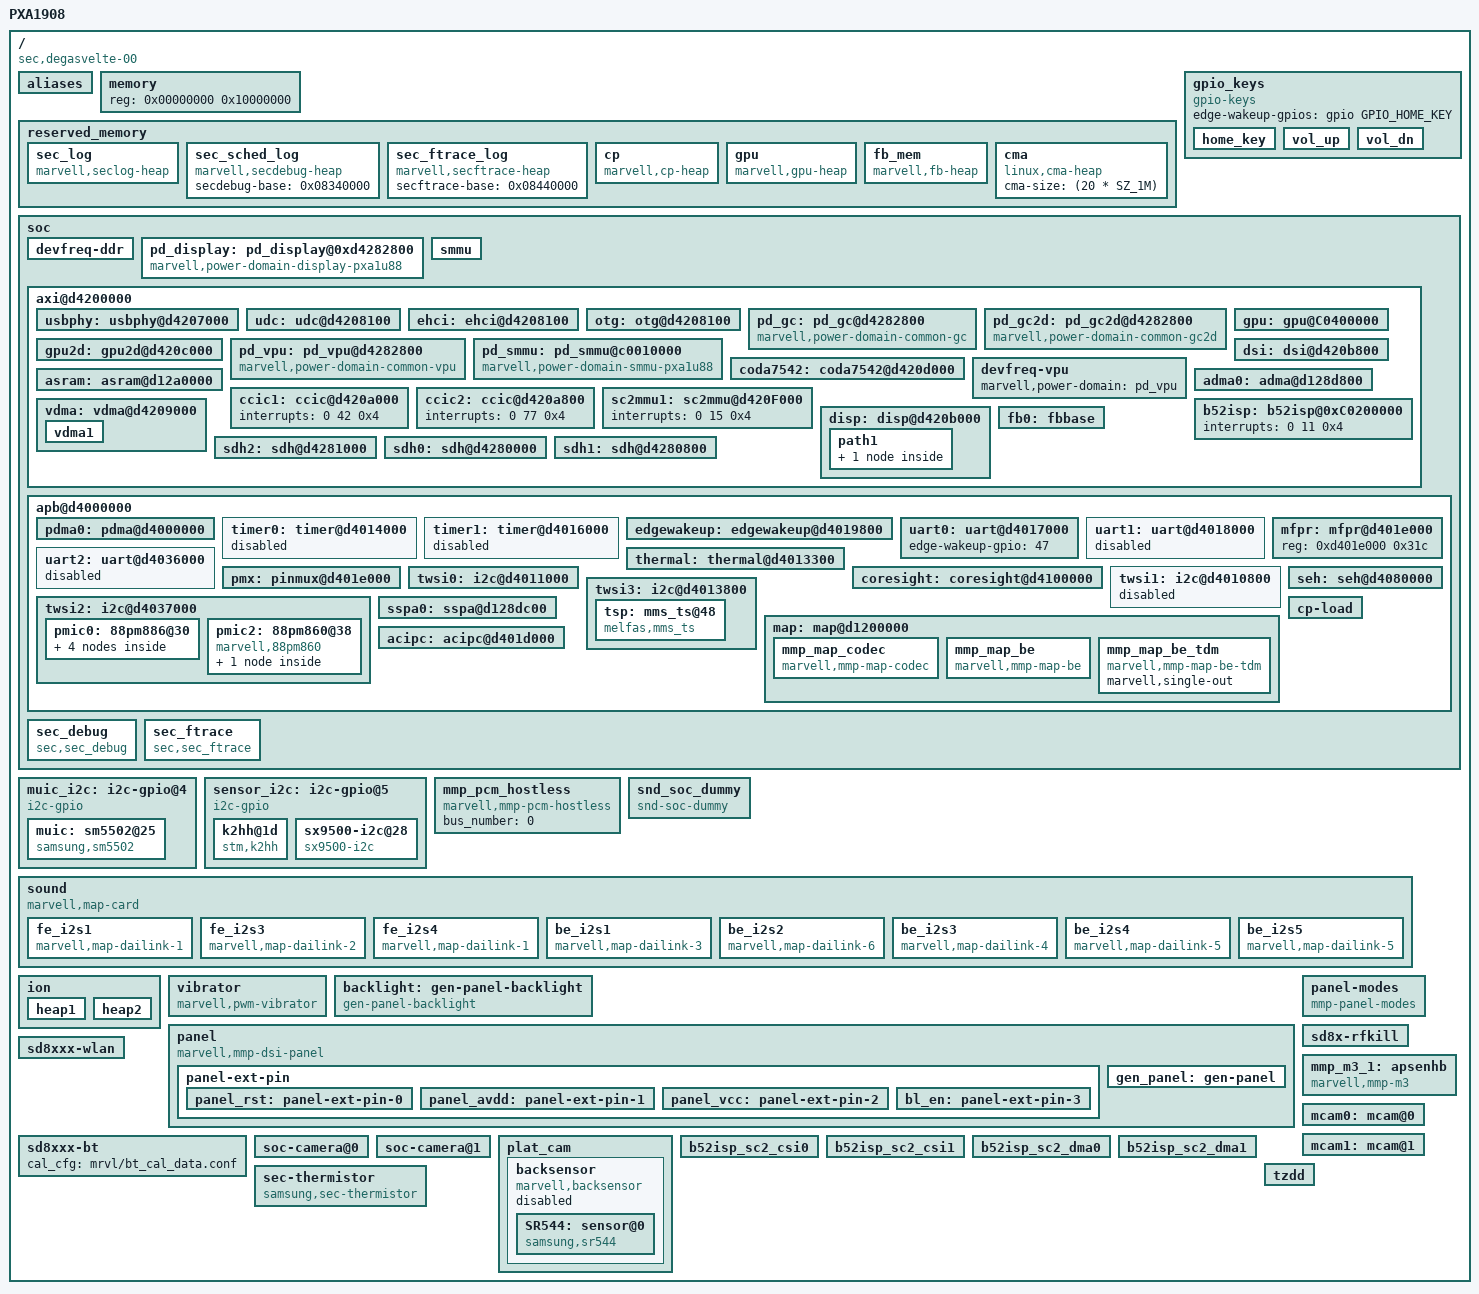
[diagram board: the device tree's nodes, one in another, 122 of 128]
/*
 *	Copyright (C) 2014 Marvell Technology Group Ltd.
 *	Copyright (C) 2014 Samsung Electronics Co, Ltd.
 *
 *	Most of configurations are taken from J1-LTE
 *
 *	This program is free software; you can redistribute it and/or modify
 *	it under the terms of the GNU General Public License version 2 as
 *	published by the Free Software Foundation.
 */

/dts-v1/;
/memreserve/ 0x0a000000 0x00080000;     /* CM3 shared buffer(512KB) */
#include "pxa1908.dtsi"
#include "pxa1908-pinfunc.h"
#include <dt-bindings/mmc/pxa_sdhci.h>
#include <dt-bindings/sizes.h>

#include "pxa1908-degasvelte-00-gpio.h"

#include "sec-machtypes.h"

#include <dt-bindings/input/input.h>
#include <dt-bindings/input/sec_input.h>

/ {
	model = "PXA1908";
	compatible = "sec,degasvelte-00", "marvell,pxa1908";
	pxa,rev-id = <MACH_TYPE_DEGASVELTE 0>;

	aliases {
		i2c4 = &muic_i2c;
		i2c5 = &sensor_i2c;
	};

	memory {
		reg = <0x00000000 0x10000000>;
	};

	reserved_memory {
		sec_log {
			compatible = "marvell,seclog-heap";
			seclog-base = <0x08140000>;
			seclog-size = <0x00100000>;
			seclastklog-base = <0x8240000>;
			seclastklog-size = <0x100000>;
			status = "okay";
		};

		sec_sched_log {
			compatible = "marvell,secdebug-heap";
			secdebug-base = <0x08340000>;
			status = "okay";
		};

		sec_ftrace_log {
			compatible = "marvell,secftrace-heap";
			secftrace-base = <0x08440000>;
			status = "okay";
		};

		cp {
			compatible = "marvell,cp-heap";
			cp-base = <0x05000000>;
			cp-size = <(48 * SZ_1M)>;
			status = "okay";
		};

		gpu {
			compatible = "marvell,gpu-heap";
			gpu-base = <0x09000000>;
			gpu-size = <(16 * SZ_1M)>;
			status = "okay";
		};

		fb_mem {
			compatible = "marvell,fb-heap";
			fb-mem = <0x17000000>;
			xres = <800>;
			yres = <1280>;
			bpp = <4>; /* bits per pixel = 32, so bytes per pixel = 32/8 = 4 */
			status = "okay";
		};

		cma {
			compatible = "linux,cma-heap";
			cma-size = <(20 * SZ_1M)>;
			status = "okay";
		};
	};

	gpio_keys: gpio_keys {	/* TODO: PINCTRL */
		compatible = "gpio-keys";
		edge-wakeup-gpios = <&gpio GPIO_HOME_KEY 0>;
		#address-cells = <1>;
		#size-cells = <0>;

		home_key {
			label = "HOME_KEY";
			linux,code = <KEY_HOMEPAGE>;
			gpios = <&gpio GPIO_HOME_KEY 1>;
		};

		vol_up {
			label = "VOL_UP";
			linux,code = <KEY_VOLUMEUP>;
			gpios = <&gpio GPIO_VOL_UP 1>;
		};

		vol_dn {
			label = "VOL_DN";
			linux,code = <KEY_VOLUMEDOWN>;
			gpios = <&gpio GPIO_VOL_DN 1>;
		};
	};

	soc {
		devfreq-ddr {
			status = "okay";
		};

		pd_display: pd_display@0xd4282800 {
			compatible = "marvell,power-domain-display-pxa1u88";
			reg = <0xd4282800 0x1000>;
			clocks = <&soc_clocks PXA1U88_CLK_DISP_HCLK>,
				<&soc_clocks PXA1U88_CLK_DSI_ESC>,
				<&soc_clocks PXA1U88_CLK_DISP1_EN>;
			clock-names = "LCDCIHCLK", "esc_clk", "disp1_clk_gate";
		};

		smmu {  /* iommu in vpu */
			clocks = <&soc_clocks PXA1U88_CLK_VPU>,
				<&soc_clocks PXA1U88_CLK_VPUBUS>;
			clock-names = "VPUCLK", "VPUACLK";
			marvell,power-domain = <&pd_vpu>;
			status = "okay";
		};

		axi@d4200000 {  /* AXI */
			usbphy: usbphy@d4207000 {
				status = "okay";
			};

			udc: udc@d4208100 {
				status = "okay";
			};

			ehci: ehci@d4208100 {
				status = "okay";
			};

			otg: otg@d4208100 {
				status = "okay";
			};

			pd_gc: pd_gc@d4282800 {
				compatible = "marvell,power-domain-common-gc";
				reg = <0xd4282800 0x1000>;
				clocks = <&soc_clocks PXA1U88_CLK_GC3D>;
				lpm-qos = <PM_QOS_CPUIDLE_BLOCK_DDR>;
			};

			pd_gc2d: pd_gc2d@d4282800 {
				compatible = "marvell,power-domain-common-gc2d";
				reg = <0xd4282800 0x1000>;
				clocks = <&soc_clocks PXA1U88_CLK_GC2D>;
				lpm-qos = <PM_QOS_CPUIDLE_BLOCK_DDR>;
			};

			gpu: gpu@C0400000 {
				marvell,power-domain = <&pd_gc>;
				marvell,gpu-mem-base = <0x09000000>;
				marvell,gpu-mem-size = <0x1000000>;
				clocks = <&soc_clocks PXA1U88_CLK_GC3D>,
					<&soc_clocks PXA1U88_CLK_GCSH>,
					<&soc_clocks PXA1U88_CLK_GCBUS>;
				clock-names = "GC3DFCLK", "GCSHCLK", "GC3DACLK";
				status = "okay";
			};

			gpu2d: gpu2d@d420c000 {
				marvell,power-domain = <&pd_gc2d>;
				clocks = <&soc_clocks PXA1U88_CLK_GC2D>,
					<&soc_clocks PXA1U88_CLK_GCBUS>;
				clock-names = "GC2DFCLK", "GC2DACLK";
				status = "okay";
			};

			pd_vpu: pd_vpu@d4282800 {
				compatible = "marvell,power-domain-common-vpu";
				reg = <0xd4282800 0x1000>;
				clocks = <&soc_clocks PXA1U88_CLK_VPU>;
				lpm-qos = <PM_QOS_CPUIDLE_BLOCK_DDR>;
			};

			pd_smmu: pd_smmu@c0010000 {
				compatible = "marvell,power-domain-smmu-pxa1u88";
				reg = <0xc0010000 0x10000>;
				marvell,power-domain-parent = <&pd_vpu>;
				clocks = <&soc_clocks PXA1U88_CLK_VPU>,
					<&soc_clocks PXA1U88_CLK_VPUBUS>;
				clock-names = "VPUCLK", "VPUACLK";
			};

			coda7542: coda7542@d420d000 {
				marvell,sram-internal = <0>;
				marvell,nv21_support = <1>;
				marvell,seconddaxi_none = <1>;
				marvell,power-domain = <&pd_smmu>;
				clocks = <&soc_clocks PXA1U88_CLK_VPU>,
					<&soc_clocks PXA1U88_CLK_VPUBUS>;
				clock-names = "VPUCLK", "VPUACLK";
				status = "okay";
			};

			devfreq-vpu {
				marvell,power-domain = <&pd_vpu>;
				status = "okay";
			};

			dsi: dsi@d420b800 {
				marvell,phy-name = "mmp_dsi1";
				marvell,plat-path-name = "mmp_pnpath";
				marvell,dsi-lanes = <4>;
				marvell,burst-mode = <2>;
				marvell,vsync-slave;
/*				marvell,hbp-en;*/
/*				marvell,hfp-en;*/
				status = "okay";
			};

			asram: asram@d12a0000 {
				status = "okay";
			};

			adma0: adma@d128d800 {
				status = "okay";
			};

			ccic1: ccic@d420a000 {	/* TODO: PINCTRL */
				interrupts = <0 42 0x4>;
				status = "okay";
			};

			ccic2: ccic@d420a800 {	/* TODO: PINCTRL */
				interrupts = <0 77 0x4>;
				status = "okay";
			};

			sc2mmu1: sc2mmu@d420F000 {
				interrupts = <0 15 0x4>;
				status = "okay";
			};

			b52isp: b52isp@0xC0200000 {
				interrupts = <0 11 0x4>;
				status = "okay";
			};

			vdma: vdma@d4209000 {
				marvell,vdma-num = <1>;
				marvell,vdma-axi = <1>;
				status = "okay";
				vdma1 {
					marvell,vdma-id = <0>;
					marvell,sram-size = <15360>;
					marvell,is_vid = <0>;
				};
			};

			disp: disp@d420b000 {
				pinctrl-names = "default";
				marvell,disp-name = "disp_name";
				marvell,path-num = <1>;
				marvell,power-domain = <&pd_display>;
				clocks = <&soc_clocks PXA1U88_CLK_DISP1>,
						<&soc_clocks PXA1U88_CLK_DISP4>;
				clock-names = "disp1_clk", "dsipll_clk";
				status = "okay";
				path1 {
					marvell,path-name = "mmp_pnpath";
					marvell,overlay-num = <1>;
					marvell,overlay-table = <1>;
					marvell,output-type = <1>;
					marvell,path-config = <0x10>;
					marvell,link-config = <0x1>;
					disp_apmu {
						plat = <4>;
						apmu-reg = <0xd428284c>;
						clksrc-bit = <9>;
						parent1-clk-tbl = "disp1_sel_clk", "dsi_pll";
						parent2-clk-tbl = "pll1_624", "pll1_832", "pll1_499", "pll4", "pll4_div3";
					};
				};
			};

			fb0: fbbase {
				marvell,fb-name = "mmp-fb";
				marvell,path-name = "mmp_pnpath";
				marvell,overlay-id = <1>;
				marvell,default-pixfmt = <0x109>;
				marvell,buffer-num = <3>;
				marvell,fb-mem = <0x17000000>;
				status = "okay";
                        };

			/* eMMC */
			sdh2: sdh@d4281000 {
				bus-width = <8>;
				non-removable;
				marvell,sdh-pm-runtime-en;
				marvell,sdh-quirks = <(SDHCI_QUIRK_BROKEN_CARD_DETECTION)>;
				marvell,sdh-quirks2 = <(
						SDHCI_QUIRK2_TUNING_ADMA_BROKEN |
						SDHCI_QUIRK2_TIMEOUT_SHORT
						)>;
				marvell,sdh-host-caps = <(MMC_CAP_1_8V_DDR)>;
				marvell,sdh-host-caps2 = <(
						MMC_CAP2_DISABLE_BLK_ASYNC |
						MMC_CAP2_CACHE_CTRL
						)>;
				marvell,sdh-flags = <(
						PXA_FLAG_NEW_RX_CFG_REG |
						PXA_FLAG_SD_8_BIT_CAPABLE_SLOT |
						PXA_FLAG_ENABLE_CLOCK_GATING |
						PXA_FLAG_TX_SEL_BUS_CLK
						)>;
				/* prop "sdh-dtr-data": <timing preset_rate src_rate tx_delay rx_delay sdclk_sel0 sdclk_sel1 fakeclk_en> */
				marvell,sdh-dtr-data = <PXA_MMC_TIMING_LEGACY PXA_SDH_DTR_26M PXA_SDH_DTR_104M 0 0 0 0 0>,
						<PXA_MMC_TIMING_MMC_HS PXA_SDH_DTR_52M PXA_SDH_DTR_104M 0 0 0 0 0>,
						<PXA_MMC_TIMING_UHS_DDR50 PXA_SDH_DTR_52M PXA_SDH_DTR_104M 0 0 0 0 0>,
						<PXA_MMC_TIMING_MMC_HS200 PXA_SDH_DTR_156M PXA_SDH_DTR_156M 0 0 3 0 0>,
						<PXA_MMC_TIMING_MAX PXA_SDH_DTR_PS_NONE PXA_SDH_DTR_104M 0 0 0 0 0>;
				marvell,sdh-tuning-win-limit = <100>;
				marvell,sdh-dvfs-levels = <1 7>; /* tuning from dvfs level 1 to 7 */
				marvell,sdh-tuning-mode = <PXA_SDH_TUNING_DVFS>;
				status = "okay";
			};

			/* SD card */
			sdh0: sdh@d4280000 {
				vqmmc-supply	= <&ldo6>;
				vmmc-supply	= <&ldo14>;
				cd-gpios = <&gpio 11 0>;
				cd-inverted;
				bus-width = <4>;
				wp-inverted;
				marvell,sdh-pm-runtime-en;
				marvell,sdh-host-caps-disable = <( MMC_CAP_UHS_SDR104 )>;
				marvell,sdh-quirks = <(
						SDHCI_QUIRK_INVERTED_WRITE_PROTECT |
						SDHCI_QUIRK_BROKEN_CARD_DETECTION
						)>;

				/* as HW design, only SD Card's host has AIB_MMC register */
				marvell,sdh-quirks2 = <(
						SDHCI_QUIRK2_SET_AIB_MMC |
						SDHCI_QUIRK2_TUNING_ADMA_BROKEN |
						SDHCI_QUIRK2_TIMEOUT_SHORT
						)>;
				marvell,sdh-flags = <(
						PXA_FLAG_NEW_RX_CFG_REG |
						PXA_FLAG_TX_SEL_BUS_CLK |
						PXA_FLAG_ENABLE_CLOCK_GATING
						)>;
				/* prop "sdh-dtr-data": <timing preset_rate src_rate tx_delay rx_delay sdclk_sel0 sdclk_sel1 fakeclk_en> */
				marvell,sdh-dtr-data = <PXA_MMC_TIMING_LEGACY PXA_SDH_DTR_26M PXA_SDH_DTR_104M 0 0 0 0 0>,
						<PXA_MMC_TIMING_SD_HS PXA_SDH_DTR_52M PXA_SDH_DTR_104M 0 0 0 0 0>,
						<PXA_MMC_TIMING_UHS_DDR50 PXA_SDH_DTR_52M PXA_SDH_DTR_104M 0 0 0 0 0>,
						<PXA_MMC_TIMING_UHS_SDR104 PXA_SDH_DTR_208M PXA_SDH_DTR_208M 0 0 3 0 0>,
						<PXA_MMC_TIMING_MAX PXA_SDH_DTR_PS_NONE PXA_SDH_DTR_104M 0 0 0 0 0>;
				marvell,sdh-tuning-win-limit = <120>;
				marvell,sdh-dvfs-levels = <1 7>; /* tuning from dvfs level 1 to 7 */
				marvell,sdh-tuning-mode = <PXA_SDH_TUNING_DVFS>;
				status = "okay";
			};

			/* SDIO */
			sdh1: sdh@d4280800 {
				bus-width = <4>;
				marvell,sdh-pm-runtime-en;
				marvell,sdh-host-caps-disable = <(MMC_CAP_UHS_SDR104 | MMC_CAP_UHS_SDR50)>;
				marvell,sdh-quirks = <(SDHCI_QUIRK_BROKEN_CARD_DETECTION)>;
				marvell,sdh-quirks2 = <(SDHCI_QUIRK2_HOLDSUSPEND_AFTER_REQUEST |
						SDHCI_QUIRK2_FAKE_SDIO_IRQ_IN_UHS |
						SDHCI_QUIRK2_TUNING_ADMA_BROKEN |
						SDHCI_QUIRK2_TIMEOUT_SHORT
						)>;
				marvell,sdh-pm-caps = <(MMC_PM_KEEP_POWER)>;
				marvell,sdh-host-caps2 = <(MMC_CAP2_NO_VOLTAGE_SWITCH)>;
				marvell,sdh-flags = <(
						PXA_FLAG_NEW_RX_CFG_REG |
						PXA_FLAG_WAKEUP_HOST |
						PXA_FLAG_TX_SEL_BUS_CLK |
						PXA_FLAG_EN_PM_RUNTIME |
						PXA_FLAG_DISABLE_PROBE_CDSCAN
						)>;
				/* prop "sdh-dtr-data": <timing preset_rate src_rate tx_delay rx_delay sdclk_sel0 sdclk_sel1 fakeclk_en> */
				marvell,sdh-dtr-data = <PXA_MMC_TIMING_LEGACY PXA_SDH_DTR_26M PXA_SDH_DTR_104M 0 0 0 0 0>,
						<PXA_MMC_TIMING_SD_HS PXA_SDH_DTR_45M PXA_SDH_DTR_89M 0 0 0 0 0>,
						<PXA_MMC_TIMING_UHS_SDR50 PXA_SDH_DTR_104M PXA_SDH_DTR_104M 0 0 0 0 0>,
						<PXA_MMC_TIMING_UHS_SDR104 PXA_SDH_DTR_208M PXA_SDH_DTR_208M 0 0 3 0 0>,
						<PXA_MMC_TIMING_MAX PXA_SDH_DTR_PS_NONE PXA_SDH_DTR_89M 0 0 0 0 0>;
				marvell,sdh-tuning-win-limit = <120>;
				marvell,sdh-dvfs-levels = <1 7>; /* tuning from dvfs level 1 to 7 */
				marvell,sdh-tuning-mode = <PXA_SDH_TUNING_DVFS>;
				status = "okay";
			};
		};

		apb@d4000000 {
			pdma0: pdma@d4000000 {
				status = "okay";
			};

			timer0: timer@d4014000 {
				status = "disabled";
			};

			timer1: timer@d4016000 {
				status = "disabled";
			};

			edgewakeup: edgewakeup@d4019800 {
				status = "okay";
			};

			uart0: uart@d4017000 {	/* TODO: PINCTRL */
				edge-wakeup-gpio = <47>; /* GPIO47: UART rx pin */
				status = "okay";
			};

			uart1: uart@d4018000 {	/* TODO: PINCTRL - disabled */
				status = "disabled";
			};

			uart2: uart@d4036000 {	/* TODO: PINCTRL - disabled */
				status = "disabled";
			};

			thermal: thermal@d4013300 {
				/*
					One line indicate for one cooling state
					first column for cpufreq constraint,
					second column for hotplug constraint.
					example:
					core-p0 = <1 0
						   3 0>;
					means: when temp get higher, apply 4 * 1.5G -> 4 * 1.2G
					when temp get more higher, apply 4 * 1.2G -> 4 * 0.8G
					From SV model, supported cooling state is as below:
					<1 0	<0 2	<1 0	<0 2
					 3 0>	 3 0>	 2 2>	 2 2>

				*/
				core-p0 = <1 0
					   3 0>;
				/*
					thermal safe 624M *4 or 800M * 2, thus supported
					<4 0> <3 2>
				*/
				thermal_safe-p0 = <4 0>;
				status = "okay";
			};

			pmx: pinmux@d401e000 {
				status = "okay";
				/* pin base, nr pins & gpio function */
				pinctrl-single,gpio-range = <
					/*
					 * GPIO number is hardcoded for range at here.
					 * In gpio chip, GPIO number is not hardcoded for range.
					 * Since one gpio pin may be routed to multiple pins,
					 * define these gpio range in pxa910-dkb.dts not pxa910.dtsi.
					 */
					&range 55 55 0	/* GPIO0 ~ GPIO54 */
					&range 110 32 0 /* GPIO67 ~ GPIO98 */
					&range 52 1 0	/* GPIO124 */
				>;
			};

			coresight: coresight@d4100000 {
				status = "okay";
			};

			mfpr: mfpr@d401e000 {
				reg = <0xd401e000 0x31c>;
				status = "okay";
			};

			twsi0: i2c@d4011000 {	/* TODO: PINCTRL */
				/* FIXME: ccic2 module will take this i2c-bus */
				status = "okay";
		        };

			twsi1: i2c@d4010800 {	/* TODO: PINCTRL - disabled */
				status = "disabled";
			};

			twsi2: i2c@d4037000 {
				status = "okay";

				pmic0: 88pm886@30 {
					reg = <0x30>;
					interrupts = <0 4 IRQF_TRIGGER_HIGH>;
					interrupt-parent = <&gic>;

					onkey {
						marvell,pm886-onkey-gpio-number = <0>;
					};

					vbus {
						gpadc-number = <1>;
					};

					battery {
						gpadc-det-no = <2>;
						gpadc-temp-no = <3>;
					};

					dvc: dvc {	/* TODO: PINCTRL */
						status = "okay";
					};
				};

				pmic2: 88pm860@38 {
					compatible = "marvell,88pm860";
					reg = <0x38>;
					marvell,pmic-type = <1>;
					/* no codec_int currently, comment out now */
					/*
					interrupt-parent = <&gpio>;
					interrupts = <124 0x1>;
					marvell,88pm805-irq-write-clear;
					*/
					pm860_codec: pm860_codec {
						compatible = "marvell,88pm860-codec";
						#dailink-cells = <1>;
					};
				};
			};

			twsi3: i2c@d4013800 {	/* TODO: PINCTRL */
				i2c-gpio = <&gpio GPIO_TSP_SCL_1P8 0 &gpio GPIO_TSP_SDA_1P8 0>;
				status = "okay";

				tsp: mms_ts@48 {	/* TODO: PINCTRL */
					compatible = "melfas,mms_ts";
					reg = <0x48>;
					tsp_vdd-supply = <&ldo2>;
					interrupt-parent = <&gpio>;
					interrupts = <GPIO_TSP_INT IRQF_TRIGGER_FALLING>;
					irq-flag = <IRQF_ONESHOT>;
					irq-gpio = <&gpio GPIO_TSP_INT GPIO_ACTIVE_LOW>;
					mms_ts,max_x = <799>;
					mms_ts,max_y = <1279>;
					mms_ts,x_num = <30>;
					mms_ts,y_num = <18>;
					mms_ts,tsp-keycodes = <KEY_RECENT KEY_BACK KEY_DUMMY_MENU KEY_DUMMY_BACK>;
				};
			};

			/* SSPA port 0 */
			sspa0: sspa@d128dc00 {	/* TODO: PINCTRL */
				playback_period_bytes = <4096>;
				playback_buffer_bytes = <16384>;
				capture_period_bytes = <4096>;
				capture_buffer_bytes = <12288>;
				burst_size = <4>;
				#dailink-cells = <1>;
				status = "okay";
			};

			map: map@d1200000 {
				marvell,b0_fix;
				marvell,apll = <1>;
				status = "okay";
				lpm-qos = <PM_QOS_CPUIDLE_BLOCK_UDR_VCTCXO>;

				mmp_map_codec: mmp_map_codec {
					compatible = "marvell,mmp-map-codec";
					#dailink-cells = <1>;
				};

				mmp_map_be: mmp_map_be {	/* TODO: PINCTRL */
					compatible = "marvell,mmp-map-be";
					#dailink-cells = <1>;
				};

				mmp_map_be_tdm: mmp_map_be_tdm {
					compatible = "marvell,mmp-map-be-tdm";
					marvell,single-out;
					#dailink-cells = <1>;
				};
			};

			acipc: acipc@d401d000 {
				status = "okay";
			};

			seh: seh@d4080000 {
				status = "okay";
			};

			cp-load {
				status = "okay";
			};
		};

		/*
		 * ramoops:
		 * 256 KB memory starts at 0x8100000
		 * pstore dump: 2 chunks, total 64 KB, 32 KB each
		 * console size: 192 KB
		 * no dump_oops

		ramoops {
			compatible = "pstore,ramoops";
			mem-size = <0x40000>;
			mem-address = <0x8100000>;
			record-size = <0x8000>;
			console-size = <0x30000>;
			dump-oops = <0>;
			status = "okay";
		};
		*/

		sec_debug {
			compatible = "sec,sec_debug";
			status = "okay";
		};

		sec_ftrace {
			compatible = "sec,sec_ftrace";
			status = "okay";
		};
	};

	muic_i2c: i2c-gpio@4 {	/* TODO: PINCTRL */
		compatible = "i2c-gpio";
		gpios = <&gpio GPIO_MUIC_SDA_1P8 0 &gpio GPIO_MUIC_SCL_1P8 0>;
		i2c-gpio,delay-us = <3>;
		i2c-gpio,timeout-ms = <100>;
		#address-cells = <1>;
		#size-cells = <0>;
		status = "okay";

		muic: sm5502@25{	/* TODO: PINCTRL */
			compatible = "samsung,sm5502";
			reg = <0x25>;
			interrupt-parent = <&gpio>;
			interrupts = <0 IRQF_TRIGGER_FALLING>;
			connector-gpio = <&gpio GPIO_MUIC_INT 0>;
			lpm-qos = <PM_QOS_CPUIDLE_BLOCK_AXI>;
		};
	};

	sensor_i2c: i2c-gpio@5 {	/* TODO: PINCTRL */
		compatible = "i2c-gpio";
		gpios = <&gpio GPIO_SENSOR_SDA_1P8 0 &gpio GPIO_SENSOR_SCL_1P8 0>;
		i2c-gpio,delay-us = <3>;
		i2c-gpio,timeout-ms = <100>;
		#address-cells = <1>;
		#size-cells = <0>;
		status = "okay";

		k2hh@1d {
			compatible = "stm,k2hh";
			reg = <0x1d>;
			interrupt-parent = <&gpio>;
			interrupts = <10 IRQF_TRIGGER_FALLING>;
			stm,irq_gpio = <&gpio 10 0x00>;
			stm,axis_map_x = <0>;
			stm,axis_map_y = <1>;
			stm,axis_map_z = <2>;
			stm,negate_x = <1>;
			stm,negate_y = <1>;
			stm,negate_z = <1>;
			stm,poll_interval = <100>;
			stm,min_interval = <2>;
			status = "okay";
		};

		sx9500-i2c@28 {
		compatible = "sx9500-i2c";
		reg = <0x28>;
		sx9500-i2c,nirq-gpio = <&gpio 31 0x0>;
		};
	};

	mmp_pcm_hostless: mmp_pcm_hostless {
		bus_number = <0>;
		compatible = "marvell,mmp-pcm-hostless";
		#dailink-cells = <1>;
		status = "okay";
	};

	snd_soc_dummy: snd_soc_dummy {
		compatible = "snd-soc-dummy";
		#dailink-cells = <1>;
		status = "okay";
	};

	sound {
		compatible = "marvell,map-card";
		map,dapm-route =
			"ADC input1", "TDM_MIC1_CAP",
			"ADC input2", "TDM_MIC2_CAP",
			"ADC input3", "BT_VC_UL",
			"TDM_OUT1_PLAYBACK", "out1_hs_en",
			"TDM_OUT2_PLAYBACK", "out1_spkr_en",
			"BT_VC_DL", "ADC output ain3";

		fe_i2s1: fe_i2s1 {
			compatible = "marvell,map-dailink-1";
			dai-name = "MAP I2S1 audio";
			stream-name = "map i2s1";
			marvell,cpu-dai = <&sspa0 0>;
			marvell,codec-dai = <&mmp_map_codec 4>;
			marvell,dai-dynamic;
		};

		fe_i2s3: fe_i2s3 {
			compatible = "marvell,map-dailink-2";
			dai-name = "MAP I2S2 audio";
			stream-name = "map i2s2";
			marvell,cpu-dai = <&mmp_pcm_hostless 0>;
			marvell,codec-dai = <&mmp_map_codec 2>;
			marvell,dai-dynamic;
			marvell,dai-no-host-mode;
		};

		fe_i2s4: fe_i2s4 {
			compatible = "marvell,map-dailink-1";
			dai-name = "MAP I2S3 audio";
			stream-name = "map i2s3";
			marvell,cpu-dai = <&mmp_pcm_hostless 0>;
			marvell,codec-dai = <&mmp_map_codec 3>;
			marvell,dai-dynamic;
			marvell,dai-no-host-mode;
		};

		be_i2s1: be_i2s1 {
			compatible = "marvell,map-dailink-3";
			dai-name = "MAP AUXI2S audio";
			stream-name = "BT audio";
			marvell,cpu-dai = <&mmp_map_be 1>;
			marvell,codec-dai = <&snd_soc_dummy 0>;
			marvell,codec-name = "snd-soc-dummy";
			marvell,codec-dai-name = "snd-soc-dummy-dai";
			marvell,dai-no-pcm;
			marvell,dai-fixup = <0>;
		};

		be_i2s2: be_i2s2 {
			compatible = "marvell,map-dailink-6";
			dai-name = "MAP TDM hs audio";
			stream-name = "codec hs audio";
			marvell,cpu-dai = <&mmp_map_be_tdm 1>;
			marvell,codec-dai = <&pm860_codec 3>;
			marvell,playback-only;
			marvell,dai-no-pcm;
			marvell,dai-fixup = <1>;
		};

		be_i2s3: be_i2s3 {
			compatible = "marvell,map-dailink-4";
			dai-name = "MAP TDM speaker audio";
			stream-name = "codec speaker audio";
			marvell,cpu-dai = <&mmp_map_be_tdm 2>;
			marvell,codec-dai = <&pm860_codec 4>;
			marvell,playback-only;
			marvell,dai-no-pcm;
			marvell,dai-fixup = <1>;
		};

		be_i2s4: be_i2s4 {
			compatible = "marvell,map-dailink-5";
			dai-name = "MAP TDM mic1 audio";
			stream-name = "codec mic1 audio";
			marvell,cpu-dai = <&mmp_map_be_tdm 3>;
			marvell,codec-dai = <&pm860_codec 1>;
			marvell,capture-only;
			marvell,dai-no-pcm;
		};

		be_i2s5: be_i2s5 {
			compatible = "marvell,map-dailink-5";
			dai-name = "MAP TDM mic2 audio";
			stream-name = "codec mic2 audio";
			marvell,cpu-dai = <&mmp_map_be_tdm 4>;
			marvell,codec-dai = <&pm860_codec 2>;
			marvell,capture-only;
			marvell,dai-no-pcm;
		};
	};

	ion {
		marvell,ion-nr = <2>;
		marvell,ion-iommu = <1>;
		marvell,power-domain = <&pd_smmu>;
		status = "okay";

		heap1 {
			marvell,ion-name = "carveout_heap";
			marvell,ion-type = <2>;
			marvell,ion-id = <2>;
			marvell,ion-base = <0>;
			marvell,ion-size = <0>;
		};

		heap2 {
			marvell,ion-name = "system_heap";
			marvell,ion-type = <0>;
			marvell,ion-id = <0>;
		};
	};

	vibrator: vibrator {	/* TODO: PINCTRL */
		compatible = "marvell,pwm-vibrator";
		pwms = <&pwm4 0 1000>;
		min_timeout = <0>;
		duty_cycle = <800>;
		vdd_type = <1>;
		vib_ldo_en = <&gpio GPIO_MOTOR_EN GPIO_ACTIVE_HIGH>;
	};

	backlight: gen-panel-backlight {
		compatible = "gen-panel-backlight";
		gen-panel-backlight-name = "panel";
		gen-panel-backlight-brt-range = <
			0	0	/* OFF */
			10	2	/* DIM */
			10	2	/* MIN */
			143	107	/* DEF */
			255	235	/* MAX */
		>;
	};

	panel {
		compatible = "marvell,mmp-dsi-panel";
		pinctrl-names = "default", "enable", "disable";
		marvell,path-name = "mmp_pnpath";
		gen-panel = <&gen_panel>;
		gen-panel-backlight = <&backlight>;
		gen-panel-esd-en;
		gen-panel-esd-gpio = <&gpio GPIO_LCD_ESD_DET 1>;
		gen-panel-esd-type = <1>;
		/*
		 * external pin properties
		 * @regulator : <name>-supply
		 * @gpio : <name>-gpio
		 */
		panel_avdd-supply = <&ldo11>;
		panel_vcc-gpio = <&gpio GPIO_LCD_3V3_EN 0>;
		panel_rst-gpio = <&gpio GPIO_LCD_NRST 0>;
		bl_en-gpio = <&gpio GPIO_LCD_BLIC_ON 0>;
		panel-ext-pin {
			/*
			 * Three properties are required
			 * to control pwr pin
			 * @node : panel-ext-pin node
			 * @on : <0> - off / <1> - on
			 * @usec : delay time of usec
			 */
			panel-ext-pin-on = <
				&panel_vcc	1 0
				&panel_avdd	1 0
				&panel_rst	0 5000
				&panel_rst	1 20000
				&bl_en	1 0
			>;
			panel-ext-pin-off = <
				&bl_en	0 0
				&panel_rst   0	10
				&panel_vcc	0 10
				&panel_avdd	0 10
			>;

			/*
			 * There are properties to define pwr pin
			 * pin-name : pin name
			 * pin-type : <0> - GPIO, <1> - PMIC Regulator
			 */
			panel_rst: panel-ext-pin-0 {
				pin-name = "panel_rst";
				pin-type = <0>;
			};
			panel_avdd: panel-ext-pin-1 {
				pin-name = "panel_avdd";
				pin-type = <1>;
			};
			panel_vcc: panel-ext-pin-2 {
				pin-name = "panel_vcc";
				pin-type = <0>;
			};
			bl_en: panel-ext-pin-3 {
				pin-name = "bl_en";
				pin-type = <0>;
			};
		};
		gen_panel: gen-panel {};
	};
        panel-modes {
		/*
		 * xres and yres are added for calculating
		 * framebuffer size.
		 * If this node is not added, it will take default
		 * size defined in drivers/video/mmp/setup.c
		 */
		compatible = "mmp-panel-modes";
		xres = <800>;
		yres = <1280>;
	};

	sd8x-rfkill {
        sd-host = <&sdh1>;
		pd-gpio = <&gpio 98 0>;
		wib_3v3-supply = <&ldo15>;
		wib_1v8-supply = <&buck2>;
		edge-wakeup-gpio = <&gpio 39 0>;
		status = "okay";
	};

	sd8xxx-wlan {
		drv_mode = <0x5>;
		cfg80211_wext = <0xc>;
		sta_name = "wlan";
		wfd_name = "p2p";
		max_vir_bss = <1>;
		dev_cap_mask = <0xffffcfff>;
		cal_data_cfg = "mrvl/WlanCalData_ext.conf";
		txpwrlimit_cfg = "mrvl/txpwrlimit_cfg.bin";
		reg_alpha2 = "US";
		p2p_enh = <1>;
	};

	sd8xxx-bt {
		/* init_cfg = "mrvl/bt_init_cfg.conf"; */
		cal_cfg = "mrvl/bt_cal_data.conf";
	};

	mmp_m3_1: apsenhb {	/* TODO: PINCTRL */
		compatible = "marvell,mmp-m3";
		pmicver = <2>;
		/* 950000 for CM3 on, 700000 for CM3 off */
		vccmain = <950000 700000>;
		vm3pwr-supply = <&ldo3>;
		antpwr-supply = <&ldo4>;
		vccmain-supply = <&vccmain>;
		status = "okay";
	};

	mcam0:mcam@0 {
		sc2-i2c-dyn-ctrl;
		pwdn-gpios = <&gpio GPIO_3M_CAM_STBY 0>;
		reset-gpios = <&gpio GPIO_3M_CAM_NRST 0>;
		dvdd_1v2-supply = <&ldo9>;
		avdd_2v8-supply = <&ldo10>;
		dovdd_1v8-supply = <&ldo8>;
		dphy_val = <0x1806 0x00011 0xe00>;
		status = "okay";
	};

	mcam1: mcam@1 {
		sc2-i2c-dyn-ctrl;
		pwdn-gpios = <&gpio GPIO_VT_CAM_NSTBY 0>;
		reset-gpios = <&gpio GPIO_VT_CAM_NRST 0>;
		avdd_2v8-supply = <&ldo10>;
		dovdd_1v8-supply = <&ldo8>;
		dphy_val = <0xff0b05 0x00024733 0x04001000>;
		status = "okay";
	};

	soc-camera@0 {
		status = "okay";
	};

	soc-camera@1 {
		status = "okay";
	};

	plat_cam {
		status = "okay";
		backsensor {
			compatible = "marvell,backsensor";
			#address-cells = <1>;
			#size-cells = <0>;
			status = "disable";
			SR544: sensor@0 {
				compatible = "samsung,sr544";
				status = "okay";
				clocks = <&soc_clocks PXA1U88_CLK_SC2_MCLK>;
				clock-names =  "SC2MCLK";
				reg = <0x28>;
				sc2-i2c-dyn-ctrl;
				adapter = <0x1>;
				sensor-pos = <1>;
				mclk = <26000000>;
				dphy3 = <0x1500>;
				dphy5 = <0xff>;
				dphy6 = <0x1001>;
				af_2v8-supply = <&ldo9>;
				avdd_2v8-supply = <&ldo10>;
				dovdd_1v8-supply = <&ldo8>;
				pwdn-gpios = <&gpio 68 1>;
				reset-gpios = <&gpio 67 1>;
			};
		};
	};

	b52isp_sc2_csi0 {
	        status = "okay";
	};

	b52isp_sc2_csi1 {
	        status = "okay";
	};

	b52isp_sc2_dma0 {
	        status = "okay";
	};

	b52isp_sc2_dma1 {
	        status = "okay";
	};

	tzdd {
		status = "okay";
	};

	sec-thermistor {
		compatible = "samsung,sec-thermistor";
		status = "okay";
		adc-channel = <1>;

		adc_array = <92 94 96 99 101 103 105 107 109 112 114 116 118 120 123 125 127 129 131 133	/* 71 */
					135 138 140 142 144 146 148 151 153 155 157 160 162 165 167 170 172 175 177 180	/* 51 */
					182 185 187 191 195 198 201 203 205 208 211 214 217 220 223 225 228 231 234 236 /* 31 */
					239 242 245 247 250 253 256 258 261 264 266 269 271 274 277 279 282 285 287 290 /* 11 */
					292 295 298 301 303 306 308 311 314 316 319 321 324 326 329 333 338 342 347 351 /* -9 */
					355 360 364 368 373 377 382 386 390 395 399>;									/* -20 */

		temp_array = <900 890 880 870 860 850 840 830 820 810 800 790 780 770 760 750 740 730 720 710
					700 690 680 670 660 650 640 630 620 610 600 590 580 570 560 550 540 530 520 510
					500 490 480 470 460 450 440 430 420 410 400 390 380 370 360 350	340 330 320 310
					300 290 280 270 260 250 240 230 220 210 200 190 180 170 160 150 140 130 120 110
					100 90 80 70 60 50 40 30 20 10 0 (-10) (-20) (-30) (-40) (-50) (-60) (-70) (-80) (-90)
					(-100) (-110) (-120) (-130) (-140) (-150) (-160) (-170) (-180) (-190) (-200)>;

		io-channels = <&gpadc 14>;
		io-channel-names = "gpadc0_res";
		io-channel-ranges;
	};
};

#include "pxa1908-degasvelte-00-pmx.dtsi"

#include "88pm886.dtsi"
#include "88pm886_fg_data_degasvelte.dtsi"
#include "88pm886_pxa1908_j1.dtsi"
#include "88pm886_battery_degasvelte.dtsi"
#include "mmp-dsi-panel-s6d7aa0x-boe-wxga-video.dtsi"
#include "mmp-dsi-panel-s6d7aa0x-sdc-wxga-video.dtsi"
